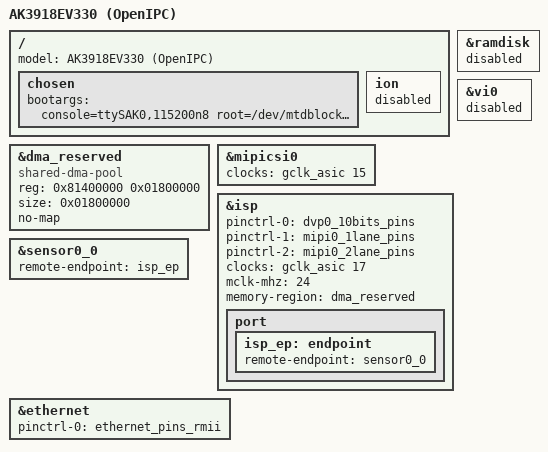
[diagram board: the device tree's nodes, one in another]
/*
 * AK3918EV330 (and its AK3916/AK3919 packages) as OpenIPC boots it:
 * Anyka's EV330 EVB with the capture path moved onto the open ISP2 host.
 * ak3918ev331-demb is this board with 128 MB.
 *
 * The bootargs are the defaults for OpenIPC's NOR layout, used whenever
 * U-Boot passes no command line of its own; U-Boot's bootargs, when present,
 * still replace them.
 */

#include "EVB_CBD_AK3918EV330_V1.0.0.dts"

/ {
	model = "AK3918EV330 (OpenIPC)";

	chosen {
		bootargs = "console=ttySAK0,115200n8 root=/dev/mtdblock3 rootfstype=squashfs init=/init mem=64M memsize=64M mtdparts=spi0.0:256k(boot),64k(env),2048k(kernel),5120k(rootfs),-(rootfs_data)";
	};

	/*
	 * The SDK hands this carve-out to its ION heap and its ramdisk for the
	 * vendor's ISP and encoder libraries. Here the open ISP2 host owns it
	 * as its capture pool, as on EV200.
	 */
	ion {
		status = "disabled";
	};
};

/* 24 MB, as the EV330 cameras' own device trees size it, not the EVB's 32. */
&dma_reserved {
	compatible = "shared-dma-pool";
	reg = <0x81400000 0x01800000>;
	size = <0x01800000>;
	no-map;
};

&ramdisk {
	/delete-property/ memory-region;
	status = "disabled";
};

/* The vendor's prebuilt host binds here; the open one binds &isp. */
&vi0 {
	status = "disabled";
};

&mipicsi0 {
	clocks = <&gclk_asic 15>;
	clock-names = "mipi_csi_clk";
	status = "okay";
};

&isp {
	pinctrl-names = "default", "mipi0_1lane", "mipi0_2lane";
	pinctrl-0 = <&dvp0_10bits_pins>;
	pinctrl-1 = <&mipi0_1lane_pins>;
	pinctrl-2 = <&mipi0_2lane_pins>;

	clocks = <&gclk_asic 17>;
	clock-names = "camera";
	mclk-mhz = <24>;
	memory-region = <&dma_reserved>;
	status = "okay";

	port {
		isp_ep: endpoint {
			remote-endpoint = <&sensor0_0>;
		};
	};
};

&sensor0_0 {
	remote-endpoint = <&isp_ep>;
};

/*
 * The RMII pads are the same on the EVB and on EV330 cameras (their own
 * device trees list GPIO 10 11 13 14 15 19 20 23 24 47), but the PHY reset
 * line is not: GPIO 82 on the EVB, GPIO 0 on at least one camera. Driving a
 * board's GPIO on the EVB's say-so could hold anything in reset, so the
 * generic board leaves the PHY as power-on reset left it.
 */
&ethernet {
	pinctrl-0 = <&ethernet_pins_rmii>;
	/delete-property/ reset-gpios;
	status = "okay";
};
